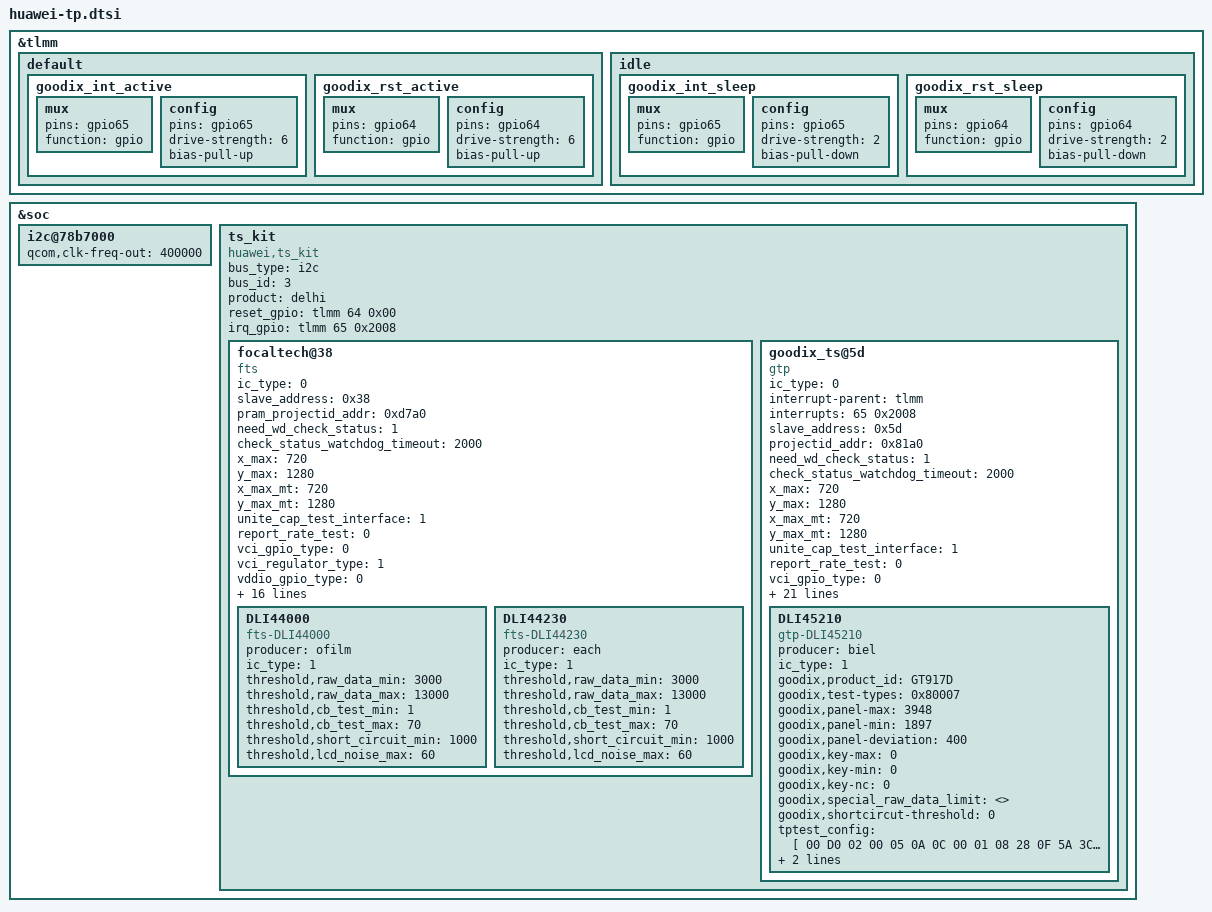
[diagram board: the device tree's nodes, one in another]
/* touch panel config */
&tlmm {

	default {
			goodix_int_active: goodix_int_active{
					mux {
						pins = "gpio65";
						function =  "gpio";
					};
					config {
						pins = "gpio65";
						/*num-grp-pins = <1>;*/
						drive-strength = <6>;
						bias-pull-up;
				};
			};

			goodix_rst_active: goodix_rst_active {
					mux {
						pins = "gpio64";
						function =  "gpio";
					};
					config {
						pins = "gpio64";
						/*num-grp-pins = <1>;*/
						drive-strength = <6>;
						bias-pull-up;
					};
			};
	};

	idle {
			goodix_int_sleep: goodix_int_sleep {
					mux {
						pins = "gpio65";
						function =  "gpio";
					};
					config {
						pins = "gpio65";
						/*num-grp-pins = <1>;*/
						drive-strength = <2>;
						bias-pull-down;
				};
			};

			goodix_rst_sleep: goodix_rst_sleep {
					mux {
						pins = "gpio64";
						function =  "gpio";
					};
					config {
						pins = "gpio64";
						/*num-grp-pins = <1>;*/
						drive-strength = <2>;
						bias-pull-down;
				};
			};
	};

};

&soc {
	i2c@78b7000{
		status = "ok";
		#address-cells = <1>;
		#size-cells = <0>;
		qcom,clk-freq-out = <400000>;
	};
	ts_kit {
		#address-cells = <1>;
		#size-cells = <0>;
		compatible = "huawei,ts_kit";
		bus_type = "i2c";
		bus_id = <3>;
		product = "delhi";
		reset_gpio = <&tlmm 64 0x00>;
		irq_gpio = <&tlmm 65 0x2008>;
		focaltech@38 {
			compatible = "fts";
			ic_type = <0>;
			slave_address = <0x38>;
			pram_projectid_addr = <0xd7a0>;
			need_wd_check_status = <1>;
			check_status_watchdog_timeout = <2000>;
			x_max = <720>;
			y_max = <1280>;
			x_max_mt = <720>;
			y_max_mt = <1280>;
			unite_cap_test_interface =<1>;
			report_rate_test =<0>;
			vci_gpio_type = <0>;
			vci_regulator_type = <1>;
			vddio_gpio_type = <0>;
			vddio_regulator_type = <1>;
			chip_id = <0x54>;
			hard_reset_delay = <200>;
			erase_min_delay = <1350>;
			calc_crc_delay = <300>;
			reboot_delay = <300>;
			erase_query_delay = <50>;
			write_flash_query_times = <30>;
			read_ecc_query_times = <100>;
			erase_flash_query_times = <15>;
			upgrade_loop_times = <5>;
			glove_switch_addr = <0xC0>;
			fts-vdd-supply = <&pm8937_l10>;
			fts-io-supply = <&pm8937_l5>;
			irq_config = <3>;/* 0-low 1-high 2-raising 3-falling */
			algo_id = <1>;
			DLI44000 {
				producer = "ofilm";
				ic_type = <1>;
				compatible = "fts-DLI44000";
				threshold,raw_data_min = <3000>;
				threshold,raw_data_max = <13000>;
				threshold,cb_test_min = <1>;
				threshold,cb_test_max = <70>;
				threshold,short_circuit_min = <1000>;
				//threshold,open_test_cb_min = <100>;
				threshold,lcd_noise_max = <60>;
			};

			DLI44230 {
				producer = "each";
				ic_type = <1>;
				compatible = "fts-DLI44230";
				threshold,raw_data_min = <3000>;
				threshold,raw_data_max = <13000>;
				threshold,cb_test_min = <1>;
				threshold,cb_test_max = <70>;
				threshold,short_circuit_min = <1000>;
				//threshold,open_test_cb_min = <100>;
				threshold,lcd_noise_max = <60>;
			};

		};

		goodix_ts@5d {
			compatible = "gtp";
			ic_type = <0>;
			interrupt-parent = <&tlmm>;
			interrupts = <65 0x2008>;
			slave_address = <0x5d>;
			projectid_addr = <0x81a0>;
			need_wd_check_status = <1>;
			check_status_watchdog_timeout = <2000>;
			x_max = <720>;
			y_max = <1280>;
			x_max_mt = <720>;
			y_max_mt = <1280>;
			unite_cap_test_interface =<1>;
			report_rate_test =<0>;
			vci_gpio_type = <0>;
			vci_regulator_type = <1>;
			vddio_gpio_type = <0>;
			vddio_regulator_type = <1>;
			chip_id = <0x87>;
			hard_reset_delay = <200>;
			erase_min_delay = <1350>;
			calc_crc_delay = <300>;
			reboot_delay = <300>;
			erase_query_delay = <50>;
			write_flash_query_times = <30>;
			read_ecc_query_times = <100>;
			erase_flash_query_times = <15>;
			upgrade_loop_times = <5>;
			glove_switch_addr = <0xC0>;
			pinctrl-names = "default","idle";
			pinctrl-0 = <&goodix_int_active &goodix_rst_active>;
			pinctrl-1 = <&goodix_int_sleep &goodix_rst_sleep>;
			goodix-vdd-supply = <&pm8937_l10>;
			goodix-io-supply = <&pm8937_l5>;
			irq_config = <2>;/* 0-low 1-high 2-raising 3-falling */
			algo_id = <1>;
			DLI45210 {
				producer = "biel";
				ic_type = <1>;
				compatible = "gtp-DLI45210";
				goodix,product_id = "GT917D";
				goodix,test-types = <0x80007>;/*test types*/
				goodix,panel-max = <3948>;
				goodix,panel-min = <1897>;
				goodix,panel-deviation = <400>;
				goodix,key-max = <0>;
				goodix,key-min = <0>;
				goodix,key-nc = <0>;/*key test not check*/
				goodix,special_raw_data_limit = <>;
				goodix,shortcircut-threshold = <0>;
				tptest_config = [
									00 D0 02 00 05 0A 0C 00 01 08
									28 0F 5A 3C 03 05 00 00 00 00
									00 00 04 17 19 1E 14 87 26 BB
									4A 4C 31 0D 00 00 00 21 03 11
									00 00 00 00 00 00 00 00 00 00
									00 00 00 14 00 02 07 00 00 04
									AD 60 00 9D 6B 00 8E 78 00 80
									87 00 75 97 00 75 00 00 00 00
									00 00 00 FF FF 00 00 00 00 00
									00 00 00 00 00 00 00 00 00 00
									00 00 00 00 00 00 00 00 00 00
									00 00 0B 0C 0D 0E 0F 10 11 12
									13 14 15 0A 09 08 07 06 05 04
									03 02 01 00 FF FF FF FF FF FF
									FF FF 28 24 22 20 1F 1E 0A 05
									04 02 00 06 08 FF FF FF FF 00
									00 00 00 00 00 00 00 00 00 00
									00 00 00 00 00 00 00 00 00 00
									00 00 00 00 00 00 00 00 00 00
									00 00 00 00 00 00 00 00 00 00
									00 00 00 00 00 00 00 00 00 00
									00 00 00 00 00 00 00 00 00 00
									00 00 00 00 00 00 D3 01
								];
				normal_config = [
									50 D0 02 00 05 0A 3C 30 01 0F
									28 0F 5A 38 05 F2 00 00 60 62
									12 33 04 16 18 1D 14 C7 26 BB
									39 3B D3 07 7C 06 00 C3 33 91
									00 00 00 00 00 00 C0 0A 0C 00
									1A 28 5B 94 D0 63 08 00 00 04
									92 2B 00 80 33 00 71 3C 00 64
									47 00 5A 54 00 5A 00 00 00 00
									00 00 00 00 00 00 00 22 03 00
									00 00 00 00 17 02 40 00 0F 28
									00 00 00 00 00 06 50 00 00 00
									00 37 0B 0C 0D 0E 0F 10 11 12
									13 14 15 0A 09 08 07 06 05 04
									03 02 01 00 FF FF FF FF FF FF
									FF FF 28 24 22 20 1F 1E 0A 05
									04 02 00 06 08 FF FF FF FF 78
									31 00 00 00 87 70 12 00 28 4E
									5A 14 1E 00 00 3C 08 88 88 00
									82 86 00 3C 00 00 00 00 00 00
									00 00 00 00 00 00 32 00 00 00
									00 00 00 23 50 00 78 78 33 0A
									19 00 00 00 00 00 00 00 00 00
									00 00 00 00 00 00 D2 01
								];
			};
	   };
	};
};

